# APM32F107xx register map
File version: 1.0
CPU: CM3 r2p1, little endian, no MPU, no FPU, 4 interrupt priority bits
Registers are 32-bit, read-write, reset 0x0 unless marked. A register's access mark holds for its fields unless they carry their own. Offsets are from the block's base; [hi:lo] are bit positions; {n}, {i} and the like mark numbered series.

## OTG_FS_PWRCLK — USB on the go full speed
Base 0x50000E00
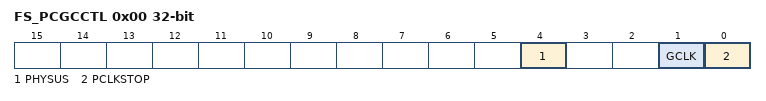
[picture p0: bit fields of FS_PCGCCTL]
0x00 FS_PCGCCTL — OTG_FS power and clock gating control register
  [4] PHYSUS — PHY Suspended
  [1] GCLK — Gate HCLK
  [0] PCLKSTOP — Stop PHY clock

## Ethernet_MAC — Ethernet: media access control
Base 0x40028000
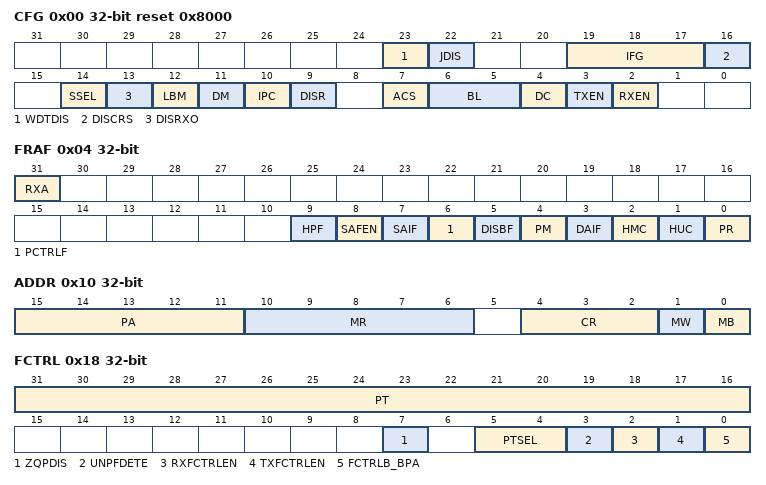
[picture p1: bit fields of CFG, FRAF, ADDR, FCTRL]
0x00 CFG reset 0x8000 — Ethernet MAC configuration register
  [23] WDTDIS — Watchdog Disable
  [22] JDIS — Jabber Disable
  [19:17] IFG — Inter-Frame Gap
  [16] DISCRS — Disable Carrier Sense During Transmission
  [14] SSEL — Speed
  [13] DISRXO — Disable Receive Own
  [12] LBM — Loopback Mode
  [11] DM — Duplex Mode
  [10] IPC — IPv4 Checksum offload
  [9] DISR — Disable Retry
  [7] ACS — Automatic Pad or CRC Stripping
  [6:5] BL — Back off Limit
  [4] DC — Deferral Check
  [3] TXEN — Transmitter Enable
  [2] RXEN — Receiver Enable
0x04 FRAF — Ethernet MAC frame filter register
  [31] RXA — Receive All
  [9] HPF — Hash or Perfect Filter
  [8] SAFEN — Source Address Filter Enable
  [7] SAIF — SA Inverse Filtering
  [6] PCTRLF — Pass Control Frames
  [5] DISBF — Disable Broadcast Frames
  [4] PM — Pass All Multicast
  [3] DAIF — DA Inverse Filtering
  [2] HMC — Hash Multicast
  [1] HUC — Hash Unicast
  [0] PR — Promiscuous Mode
0x08 HTH — Ethernet MAC hash table high register
  [31:0] HTH — Hash Table High
0x0C HTL — Ethernet MAC hash table low register
  [31:0] HTL — Hash Table Low
0x10 ADDR — Ethernet MAC MII address register
  [15:11] PA — Physical Layer Address
  [10:6] MR — MII Register
  [4:2] CR — Clock Range
  [1] MW — MII Write
  [0] MB — MII Busy
0x14 DATA — Ethernet MAC MII data register
  [15:0] MD — MII Data
0x18 FCTRL — Ethernet MAC flow control register
  [31:16] PT — Pause Time
  [7] ZQPDIS — Zero-quanta Pause Disable
  [5:4] PTSEL — Pause Threshold Select
  [3] UNPFDETE — Unicast Pause Frame Detect
  [2] RXFCTRLEN — Receive Flow Control Enable
  [1] TXFCTRLEN — Transmit Flow Control Enable
  [0] FCTRLB_BPA — Flow Control Busy/Back Pressure Activate
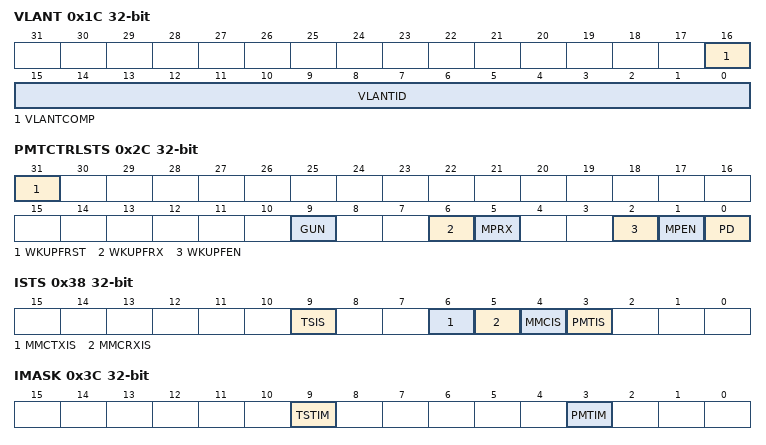
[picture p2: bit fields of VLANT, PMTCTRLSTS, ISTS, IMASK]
0x1C VLANT — Ethernet MAC VLAN tag register
  [16] VLANTCOMP — 12-bit VLAN Tag Comparison
  [15:0] VLANTID — VLAN Tag Identifier
0x28 REMWKUPFFL — Ethernet MAC PMT control and status register
0x2C PMTCTRLSTS ro — Ethernet MAC debug register
  [31] WKUPFRST — Wakeup Frame Filter Register Pointer Reset
  [9] GUN — Global Unicast
  [6] WKUPFRX — Wakeup Frame Received
  [5] MPRX — Magic Packet Received
  [2] WKUPFEN — Wakeup Frame Enable
  [1] MPEN — Magic Packet Enable
  [0] PD — Power Down
0x38 ISTS access per field — Ethernet MAC interrupt status register
  [9] TSIS rw — Timestamp Interrupt Status
  [6] MMCTXIS ro — MMC Transmit Interrupt Status
  [5] MMCRXIS ro — MMC Receive Interrupt Status
  [4] MMCIS ro — MMC Interrupt Status
  [3] PMTIS ro — PMT Interrupt Status
0x3C IMASK — Ethernet MAC interrupt mask register
  [9] TSTIM — Time Stamp Trigger Interrupt Mask
  [3] PMTIM — PMT Interrupt Mask
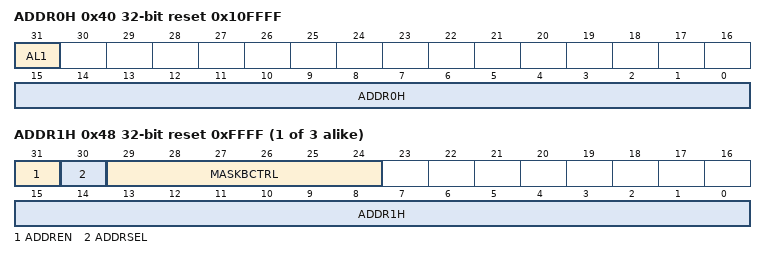
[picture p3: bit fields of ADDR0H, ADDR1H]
0x40 ADDR0H access per field reset 0x10FFFF — Ethernet MAC address 0 high register
  [31] AL1 ro — Always 1
  [15:0] ADDR0H rw — MAC address0 high
0x44 ADDR0L reset 0xFFFFFFFF — Ethernet MAC address 0 low register
  [31:0] ADDR0L — MAC Address 0
{0x40+8i} ADDR{i}H reset 0xFFFF (i=1..3) — Ethernet MAC address {i} high register
  [31] ADDREN — Address Enable
  [30] ADDRSEL — Address Select
  [29:24] MASKBCTRL — Mask Byte Control
  [15:0] ADDR{i}H — MAC Address {i}
0x4C ADDR1L reset 0xFFFFFFFF — Ethernet MAC address1 low register
  [31:0] ADDR1L — MAC Address 1
0x54 ADDR2L reset 0xFFFFFFFF — Ethernet MAC address 2 low register
  [30:0] ADDR2L — MAC Address 2
0x5C ADDR3L reset 0xFFFFFFFF — Ethernet MAC address 3 low register
  [31:0] ADDR3L — MAC Address 3

## Ethernet_MMC — Ethernet: MAC management counters
Base 0x40028100
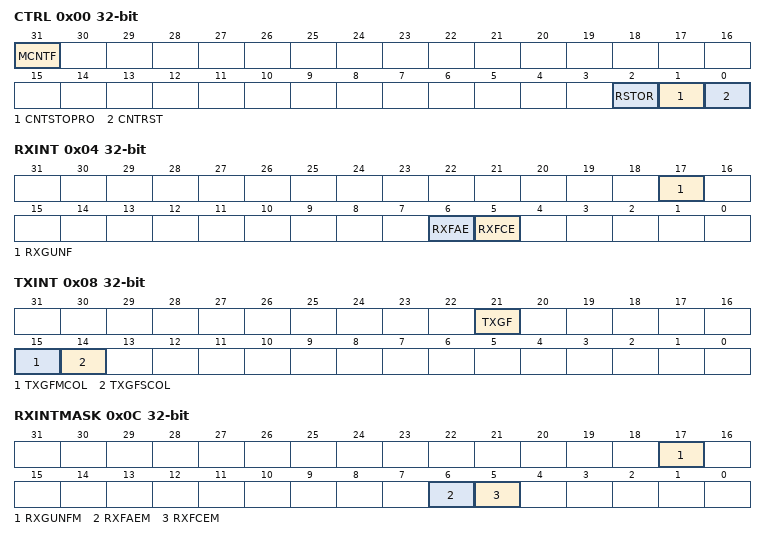
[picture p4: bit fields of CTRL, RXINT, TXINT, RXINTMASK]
0x00 CTRL — Ethernet MMC control register
  [31] MCNTF — MMC counter freeze
  [2] RSTOR — Reset on read
  [1] CNTSTOPRO — Counter stop rollover
  [0] CNTRST — Counter reset
0x04 RXINT — Ethernet MMC receive interrupt register
  [17] RXGUNF — Received Good Unicast Frames Status
  [6] RXFAE — Received frames alignment error status
  [5] RXFCE — Received frames CRC error status
0x08 TXINT — Ethernet MMC transmit interrupt register
  [21] TXGF — Transmitted good frames status
  [15] TXGFMCOL — Transmitted good frames more single collision status
  [14] TXGFSCOL — Transmitted good frames single collision status
0x0C RXINTMASK — Ethernet MMC receive interrupt mask register
  [17] RXGUNFM — Received good unicast frames mask
  [6] RXFAEM — Received frames alignment error mask
  [5] RXFCEM — Received frame CRC error mask
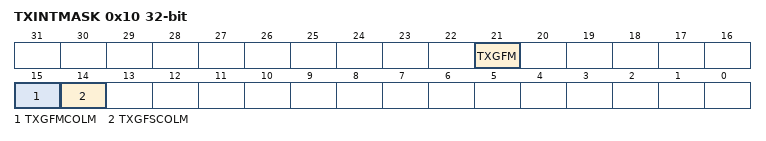
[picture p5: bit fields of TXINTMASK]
0x10 TXINTMASK — Ethernet MMC transmit interrupt mask register
  [21] TXGFM — Transmitted good frames mask
  [15] TXGFMCOLM — Transmitted good frames more single collision mask
  [14] TXGFSCOLM — Transmitted good frames single collision mask
0x4C TXGFSCCNT ro — Ethernet MMC transmitted good frames after a single collision counter
  [31:0] TXGFSCCNT — Transmitted good frames after a single collision counter
0x50 TXGFMCCNT ro — Ethernet MMC transmitted good frames after more than a single collision
  [31:0] TXGFMCCNT — Transmitted good frames after more than a single collision counter
0x68 TXGFCNT ro — Ethernet MMC transmitted good frames counter register
  [31:0] TXGFCNT — Transmitted good frames counter
0x94 RXFCECNT ro — Ethernet MMC received frames with CRC error counter register
  [31:0] RXFCECNT — Received frames with CRC error counter
0x98 RXFAECNT ro — Ethernet MMC received frames with alignment error counter register
  [31:0] RXFAECNT — Received frames with alignment error counter
0xC4 RXGUNCNT ro — MMC received good unicast frames counter register
  [31:0] RXGUNCNT — Received good unicast frames counter

## Ethernet_PTP — Ethernet: Precision time protocol
Base 0x40028700
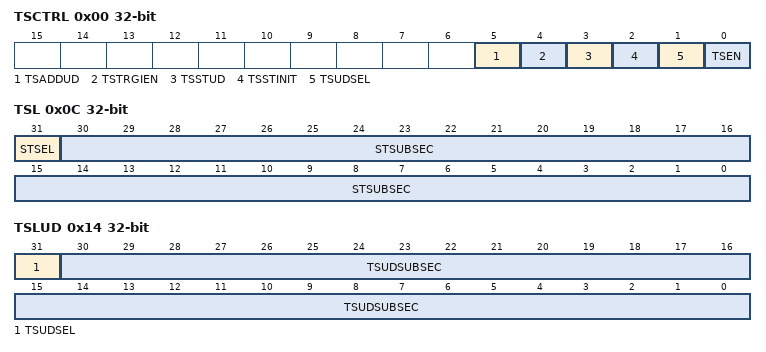
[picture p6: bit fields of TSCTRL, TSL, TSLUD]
0x00 TSCTRL — Ethernet PTP time stamp control register
  [5] TSADDUD — Time stamp addend register update
  [4] TSTRGIEN — Time stamp interrupt trigger enable
  [3] TSSTUD — Time stamp system time update
  [2] TSSTINIT — Time stamp system time initialize
  [1] TSUDSEL — Time stamp fine or coarse update
  [0] TSEN — Time stamp enable
0x04 SUBSECI — Ethernet PTP subsecond increment register
  [7:0] STSUBSECI — System time subsecond increment
0x08 TSH ro — Ethernet PTP time stamp high register
  [31:0] STSEC — System time second
0x0C TSL ro — Ethernet PTP time stamp low register
  [31] STSEL — System time positive or negative sign
  [30:0] STSUBSEC — System time subseconds
0x10 TSHUD — Ethernet PTP time stamp high update register
  [31:0] TSUDSEC — Time stamp update second
0x14 TSLUD — Ethernet PTP time stamp low update register
  [31] TSUDSEL — Time stamp update positive or negative sign
  [30:0] TSUDSUBSEC — Time stamp update subseconds
0x18 TSA — Ethernet PTP time stamp addend register
  [31:0] TSA — Time stamp addend
0x1C TTSH — Ethernet PTP target time high register
  [31:0] TTSH — Target time stamp high
0x20 TTSL — Ethernet PTP target time low register
  [31:0] TTSL — Target time stamp low
